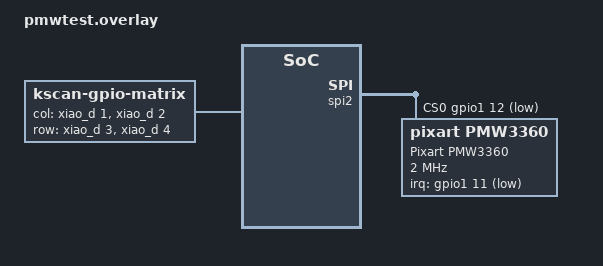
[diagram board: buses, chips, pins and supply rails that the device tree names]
/ {
    chosen {
        zmk,kscan = &kscan0;
    };

    kscan0: kscan_0 {
        compatible = "zmk,kscan-gpio-matrix";
        label = "KSCAN";
        diode-direction = "col2row";

        col-gpios
            = <&xiao_d 1 GPIO_ACTIVE_HIGH>
            , <&xiao_d 2 GPIO_ACTIVE_HIGH>
            ;

        row-gpios
            = <&xiao_d 3 (GPIO_ACTIVE_HIGH | GPIO_PULL_DOWN)>
            , <&xiao_d 4 (GPIO_ACTIVE_HIGH | GPIO_PULL_DOWN)>
            ;
    };
};

&spi2 {
    status = "okay";
    cs-gpios = <&gpio1 12 GPIO_ACTIVE_LOW>;
    pmw3360: pmw3360@0 {
        compatible = "pixart,pmw3360";
        status = "okay";
        reg = <0>;
        label = "Pixart PMW3360";
        irq-gpios = <&gpio1 11 (GPIO_ACTIVE_LOW | GPIO_PULL_UP)>;
        spi-max-frequency = <2000000>;
    };
};
